# S32K148_M4 register map
Vendor: NXP Semiconductors; File version: 1.1a
CPU: CM4 r0p1, little endian, MPU, FPU, VTOR, 4 interrupt priority bits
Registers are 32-bit, read-write, reset 0x0 unless marked. A register's access mark holds for its fields unless they carry their own. Offsets are from the block's base; [hi:lo] are bit positions.

## RTC
Base 0x4003D000
0x00 TSR — RTC Time Seconds Register
  [31:0] TSR — Time Seconds Register
0x04 TPR — RTC Time Prescaler Register
  [15:0] TPR — Time Prescaler Register
0x08 TAR — RTC Time Alarm Register
  [31:0] TAR — Time Alarm Register
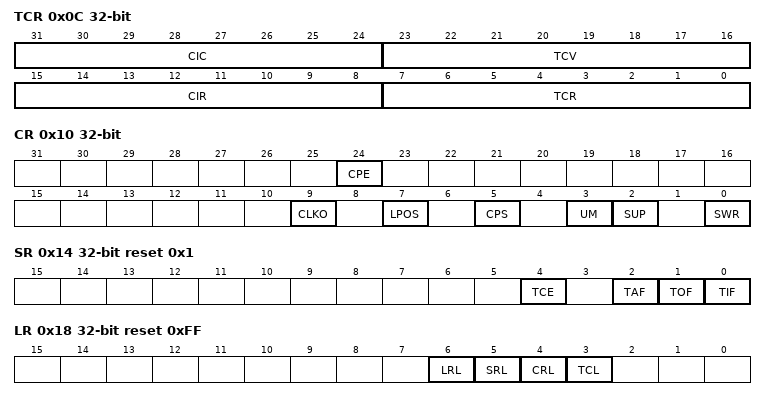
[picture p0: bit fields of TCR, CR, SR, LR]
0x0C TCR — RTC Time Compensation Register
  [31:24] CIC ro — Compensation Interval Counter
  [23:16] TCV ro — Time Compensation Value
  [15:8] CIR — Compensation Interval Register
  [7:0] TCR — Time Compensation Register
    0=Time Prescaler Register overflows every 32768 clock cycles; 1=Time Prescaler Register overflows every 32767 clock cycles; 126=Time Prescaler Register overflows every 32642 clock cycles; 127=Time Prescaler Register overflows every 32641 clock cycles; 128=Time Prescaler Register overflows every 32896 clock cycles; 129=Time Prescaler Register overflows every 32895 clock cycles; 255=Time Prescaler Register overflows every 32769 clock cycles
0x10 CR — RTC Control Register
  [24] CPE — Clock Pin Enable
    0=The RTC_CLKOUT function is disabled; 1=Enable RTC_CLKOUT function
  [9] CLKO — Clock Output
    0=The 32 kHz clock is output to other peripherals; 1=The 32 kHz clock is not output to other peripherals
  [7] LPOS — LPO Select
    0=RTC prescaler increments using 32.768 kHz clock; 1=RTC prescaler increments using 1 kHz LPO, bits [4:0] of the prescaler are ignored
  [5] CPS — Clock Pin Select
    0=The prescaler output clock (as configured by TSIC) is output on RTC_CLKOUT; 1=The RTC 32.768 kHz clock is output on RTC_CLKOUT, provided it is output to other peripherals
  [3] UM — Update Mode
    0=Registers cannot be written when locked; 1=Registers can be written when locked under limited conditions
  [2] SUP — Supervisor Access
    0=Non-supervisor mode write accesses are not supported and generate a bus error; 1=Non-supervisor mode write accesses are supported
  [0] SWR — Software Reset
    0=No effect; 1=Resets all RTC registers except for the SWR bit . The SWR bit is cleared by POR and by software explicitly clearing it.
0x14 SR reset 0x1 — RTC Status Register
  [4] TCE — Time Counter Enable
    0=Time counter is disabled; 1=Time counter is enabled
  [2] TAF ro — Time Alarm Flag
    0=Time alarm has not occurred; 1=Time alarm has occurred
  [1] TOF ro — Time Overflow Flag
    0=Time overflow has not occurred; 1=Time overflow has occurred and time counter is read as zero
  [0] TIF ro — Time Invalid Flag
    0=Time is valid; 1=Time is invalid and time counter is read as zero
0x18 LR reset 0xFF — RTC Lock Register
  [6] LRL — Lock Register Lock
    0=Lock Register is locked and writes are ignored; 1=Lock Register is not locked and writes complete as normal
  [5] SRL — Status Register Lock
    0=Status Register is locked and writes are ignored; 1=Status Register is not locked and writes complete as normal
  [4] CRL — Control Register Lock
    0=Control Register is locked and writes are ignored; 1=Control Register is not locked and writes complete as normal
  [3] TCL — Time Compensation Lock
    0=Time Compensation Register is locked and writes are ignored; 1=Time Compensation Register is not locked and writes complete as normal
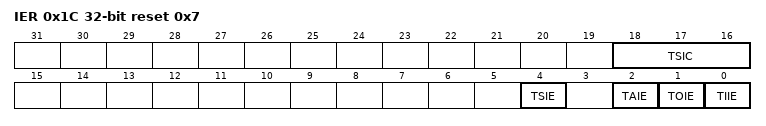
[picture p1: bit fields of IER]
0x1C IER reset 0x7 — RTC Interrupt Enable Register
  [18:16] TSIC — Timer Seconds Interrupt Configuration
    0=1 Hz; 1=2 Hz; 2=4 Hz; 3=8 Hz; 4=16 Hz; 5=32 Hz; 6=64 Hz; 7=128 Hz
  [4] TSIE — Time Seconds Interrupt Enable
    0=Seconds interrupt is disabled; 1=Seconds interrupt is enabled
  [2] TAIE — Time Alarm Interrupt Enable
    0=Time alarm flag does not generate an interrupt; 1=Time alarm flag does generate an interrupt
  [1] TOIE — Time Overflow Interrupt Enable
    0=Time overflow flag does not generate an interrupt; 1=Time overflow flag does generate an interrupt
  [0] TIIE — Time Invalid Interrupt Enable
    0=Time invalid flag does not generate an interrupt; 1=Time invalid flag does generate an interrupt
